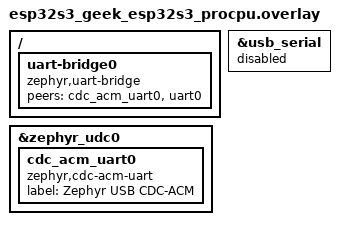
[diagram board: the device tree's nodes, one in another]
/*
 * Copyright (c) 2025 Chen Xingyu <hi@xingrz.me>
 * SPDX-License-Identifier: Apache-2.0
 */

/ {
	uart-bridge0 {
		compatible = "zephyr,uart-bridge";
		peers = <&cdc_acm_uart0 &uart0>;
	};
};

&usb_serial {
	status = "disabled";
};

&zephyr_udc0 {
	status = "okay";

	cdc_acm_uart0: cdc_acm_uart0 {
		compatible = "zephyr,cdc-acm-uart";
		label = "Zephyr USB CDC-ACM";
	};
};
